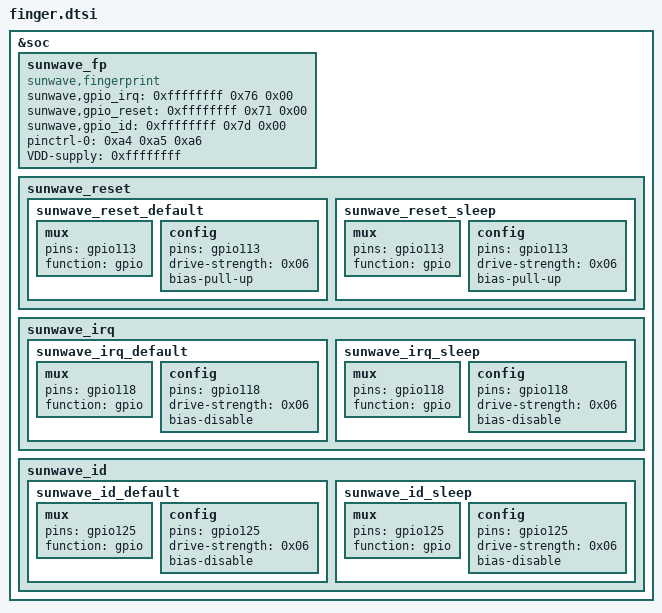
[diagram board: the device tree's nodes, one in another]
/*
 * Copyright (c) 2015-2019, The Linux Foundation. All rights reserved.
 *
 * This program is free software; you can redistribute it and/or modify
 * it under the terms of the GNU General Public License version 2 and
 * only version 2 as published by the Free Software Foundation.
 *
 * This program is distributed in the hope that it will be useful,
 * but WITHOUT ANY WARRANTY; without even the implied warranty of
 * MERCHANTABILITY or FITNESS FOR A PARTICULAR PURPOSE.  See the
 * GNU General Public License for more details.
 */
&soc {
	sunwave_fp {
		status = "ok";
		compatible = "sunwave,fingerprint";
		sunwave,gpio_irq = <0xffffffff 0x76 0x00>;
		sunwave,gpio_reset = <0xffffffff 0x71 0x00>;
		sunwave,gpio_id = <0xffffffff 0x7d 0x00>;
		pinctrl-names = "default";
		pinctrl-0 = <0xa4 0xa5 0xa6>;
		VDD-supply = <0xffffffff>;
	};

	sunwave_reset {
		sunwave_reset_default {
			mux {
				pins = "gpio113";
				function = "gpio";
			};

			config {
				pins = "gpio113";
				drive-strength = <0x06>;
				bias-pull-up;
			};
		};

		sunwave_reset_sleep {
			mux {
				pins = "gpio113";
				function = "gpio";
			};

			config {
				pins = "gpio113";
				drive-strength = <0x06>;
				bias-pull-up;
			};
		};
	};

	sunwave_irq {
		sunwave_irq_default {
			mux {
				pins = "gpio118";
				function = "gpio";
			};

			config {
				pins = "gpio118";
				drive-strength = <0x06>;
				bias-disable;
			};
		};

		sunwave_irq_sleep {
			mux {
				pins = "gpio118";
					function = "gpio";
			};

			config {
				pins = "gpio118";
				drive-strength = <0x06>;
				bias-disable;
			};
		};
	};

	sunwave_id {
		sunwave_id_default {
			mux {
				pins = "gpio125";
				function = "gpio";
			};

			config {
				pins = "gpio125";
				drive-strength = <0x06>;
				bias-disable;
			};
		};

		sunwave_id_sleep {
			mux {
				pins = "gpio125";
				function = "gpio";
			};

			config {
				pins = "gpio125";
				drive-strength = <0x06>;
				bias-disable;
			};
		};
	};
};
